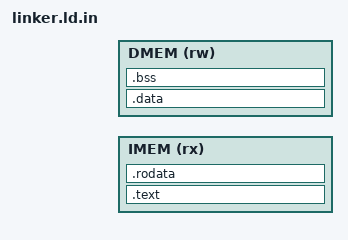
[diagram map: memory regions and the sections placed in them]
OUTPUT_ARCH("riscv")
ENTRY(_start)

MEMORY
{
    IMEM (rx) : ORIGIN = @IMEM_BASE@, LENGTH = @IMEM_SIZE@
    DMEM (rw) : ORIGIN = @DMEM_BASE@, LENGTH = @DMEM_SIZE@
}

SECTIONS
{
    .text : {
        KEEP(*(.text.entry))
        *(.init)
        *(.init*)
        *(.text)
        *(.text*)
        . = ALIGN(4);
    } > IMEM

    .rodata : {
        *(.srodata)
        *(.srodata*)
        *(.rodata)
        *(.rodata*)
        . = ALIGN(4);
    } > IMEM

    .data : {
        . = ALIGN(4);
        __data_start = .;
        __sdata_start = .;
        PROVIDE(__global_pointer$ = __sdata_start + 0x800);

        *(.sdata)
        *(.sdata*)
        *(.data)
        *(.data*)

        . = ALIGN(4);
        __data_end = .;
    } > DMEM

    .bss : {
        . = ALIGN(4);
        _sbss = .;
        __bss_start = .;

        *(.sbss)
        *(.sbss*)
        *(.scommon)
        *(.bss)
        *(.bss*)
        *(COMMON)

        . = ALIGN(4);
        _ebss = .;
        __bss_end = .;
    } > DMEM

    . = ALIGN(16);
    __end = .;
    _end = .;

    __imem_base = ORIGIN(IMEM);
    __imem_size = LENGTH(IMEM);
    __imem_end = ORIGIN(IMEM) + LENGTH(IMEM);

    __dmem_base = ORIGIN(DMEM);
    __dmem_size = LENGTH(DMEM);
    __dmem_end = ORIGIN(DMEM) + LENGTH(DMEM);

    __stack = ORIGIN(DMEM) + LENGTH(DMEM);
    __stack_top = __stack;

    ASSERT(__data_end <= ORIGIN(DMEM) + LENGTH(DMEM), "DMEM overflow in .data")
    ASSERT(__bss_end <= ORIGIN(DMEM) + LENGTH(DMEM), "DMEM overflow in .bss")

    /DISCARD/ : {
        *(.comment)
        *(.eh_frame)
        *(.riscv.attributes)
        *(.note*)
    }
}
